# ESP32 register map
Vendor: ESPRESSIF SYSTEMS (SHANGHAI) CO., LTD.; Series: ESP32 Series; File version: 17
CPU: Xtensa LX6 r0p0, little endian, no MPU, FPU, 0 interrupt priority bits
Address unit: 32 bits
Registers are 32-bit, read-write, reset 0x0 unless marked. A register's access mark holds for its fields unless they carry their own. Offsets are from the block's base; [hi:lo] are bit positions; lines under a group give offsets from that group; {n}, {i} and the like mark numbered series.

## WIFI — MAC controller for Wi-Fi peripheral
Base 0x3FF73000
{0x0+0x40*i} FILTER_BANK{i} (i=0..1) group — Filter banks for frame reception. Bank zero is for the BSSID and bank one for the RA. Each filter bank has registers for two interfaces.
  {0x0+8j} ADDR_LOW{j} (j=0..3) — First 4 bytes of BSSID MAC address filter
  {0x4+8j} ADDR_HIGH{j} (j=0..3) — last 2 bytes of BSSID MAC address filter
    [15:0] ADDR
  {0x20+8j} MASK_LOW{j} (j=0..3) — First 4 bytes of BSSID MAC address filter mask
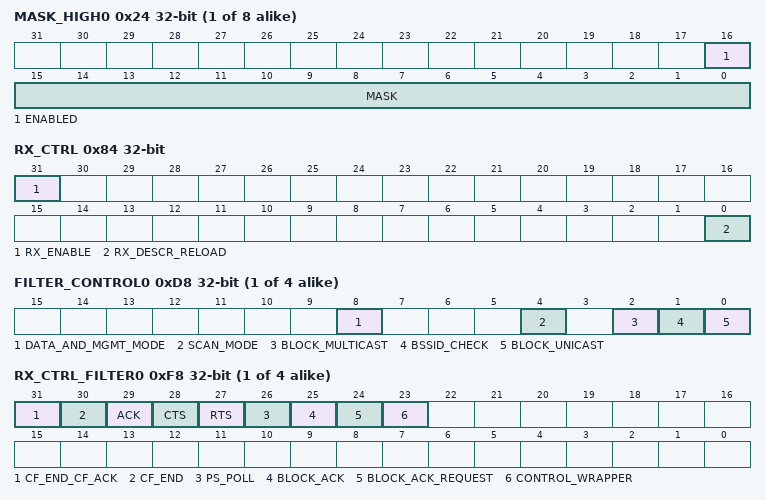
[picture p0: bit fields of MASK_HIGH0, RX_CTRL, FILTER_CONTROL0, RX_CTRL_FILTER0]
  {0x24+8j} MASK_HIGH{j} (j=0..3) — last 2 bytes of BSSID MAC address filter mask
    [16] ENABLED, [15:0] MASK
0x84 RX_CTRL — Controls the reception of frames
  [31] RX_ENABLE — Enable frame reception
  [0] RX_DESCR_RELOAD — Instruct the hardware to reload the RX descriptors
0x88 RX_DMA_LIST group
  0x00 RX_DESCR_BASE access not given — base address of the RX DMA list
  0x04 RX_DESCR_NEXT — next item in the RX DMA list
  0x08 RX_DESCR_LAST — last item in RX DMA list
{0xD8+4i} FILTER_CONTROL{i} (i=0..3) — Controls the RX filter for an interface
  [8] DATA_AND_MGMT_MODE — Receive everything except control frames
  [4] SCAN_MODE — Receive beacon frames
  [2] BLOCK_MULTICAST — Block multicast frames not matching the address filter
  [1] BSSID_CHECK — Check BSSID for filtering
  [0] BLOCK_UNICAST — Block unicast frames not matching the address filter
{0xF8+4i} RX_CTRL_FILTER{i} (i=0..3) — Configures which control frames pass the RX filter. Setting a bit lets that frame type pass the filter.
  [31] CF_END_CF_ACK — Filter CF-End+CF-Ack frames
  [30] CF_END — Filter CF-End frames
  [29] ACK — Filter ACK frames
  [28] CTS — Filter CTS frames
  [27] RTS — Filter RTS frames
  [26] PS_POLL — Filter PS-Poll frames
  [25] BLOCK_ACK — Filter Block ACK frames
  [24] BLOCK_ACK_REQUEST — Filter Block ACK Request frames
  [23] CONTROL_WRAPPER — Filter Control Wrapper frames
0x2BC HW_STAT_ACK_INT access not given
0x2C0 HW_STAT_RTS_INT access not given
0x2C4 HW_STAT_CTS_INT access not given
0x2C8 HW_STAT_RIFS_INT access not given
0x2CC HW_STAT_RX_SUCCESS access not given
0x2D0 HW_STAT_RX_END access not given
0x2D8 HW_STAT_HOP_ERR access not given
0x2DC HW_STAT_FULL2 access not given
0x2E0 HW_STAT_BLOCK_ERR access not given
0x800 CRYPTO_CONTROL group — Control registers for hardware crypto
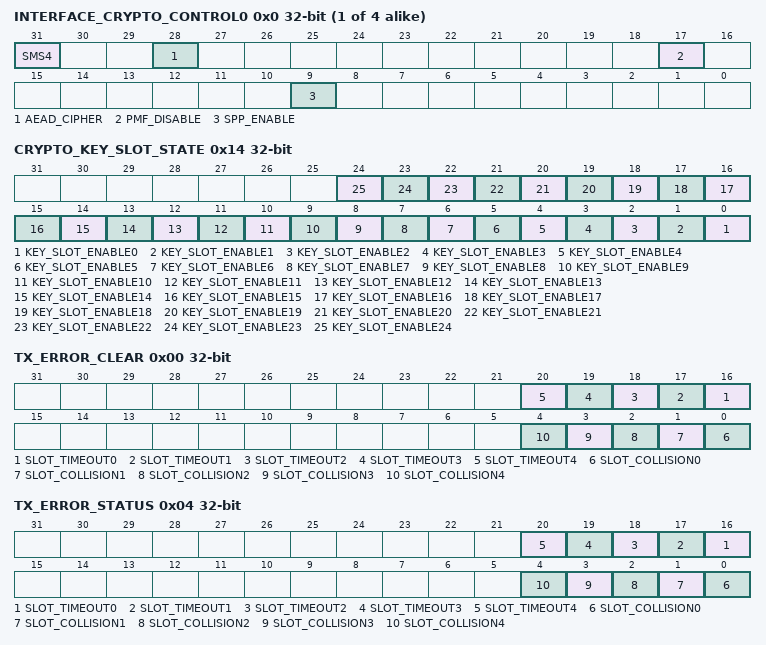
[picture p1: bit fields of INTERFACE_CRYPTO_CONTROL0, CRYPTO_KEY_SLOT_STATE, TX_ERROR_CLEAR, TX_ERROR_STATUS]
  {0x0+4j} INTERFACE_CRYPTO_CONTROL{j} (j=0..3) — Control over cryptographic parameters for a specific interface
    [31] SMS4 — Cipher is SMS4
    [28] AEAD_CIPHER — Does the cipher employ Authenticated Encryption with Associated Data (AEAD)
    [17] PMF_DISABLE — Disable Protected Management Frames (PMF)
    [9] SPP_ENABLE — Enable Signaling and Payload Protection (SPP) for A-MSDUs
  0x10 GENERAL_CRYPTO_CONTROL — Control over the whole crypto unit
  0x14 CRYPTO_KEY_SLOT_STATE — State of cryptographic key slots
    [n] KEY_SLOT_ENABLE{n} (n=0..24) — Enable the key slot corresponding to this bit
0xC00 MAC_TIME access not given — Current value of the MAC timer
0xC48 MAC_INTERRUPT group — Status and clear for the Wi-Fi MAC interrupt
  0x00 WIFI_INT_STATUS access not given — Interrupt status of WIFI peripheral
  0x04 WIFI_INT_CLEAR access not given — Interrupt status clear of WIFI peripheral
0xCB8 CTRL — Exact name and meaning unknown, used for initializing the MAC
0xCBC TXQ_STATE group — State of transmission queues
  0x00 TX_ERROR_CLEAR access not given — Clear the error status of a slot
    [n+16] SLOT_TIMEOUT{n} (n=0..4) — Timeout clear bit for a slot
    [n] SLOT_COLLISION{n} (n=0..4) — Collision clear bit for a slot
  0x04 TX_ERROR_STATUS access not given — Error status of a slot
    [n+16] SLOT_TIMEOUT{n} (n=0..4) — Timeout status bit for a slot
    [n] SLOT_COLLISION{n} (n=0..4) — Collision status bit for a slot
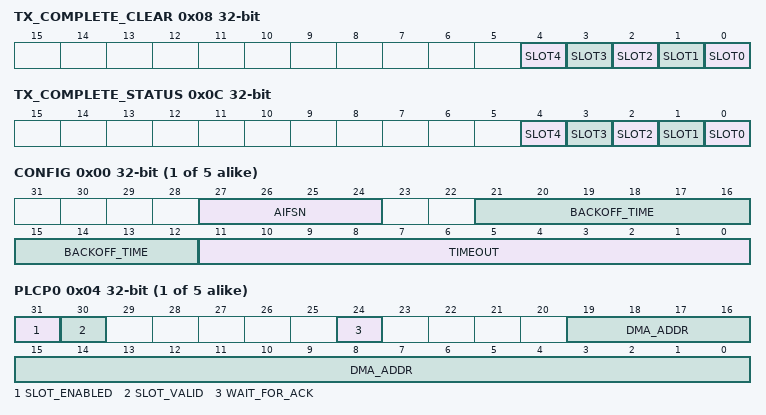
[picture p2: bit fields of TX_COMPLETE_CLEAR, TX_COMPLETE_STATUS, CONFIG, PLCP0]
  0x08 TX_COMPLETE_CLEAR access not given — Clear the completion status of a slot
    [n] SLOT{n} (n=0..4) — Clear bit for a slot
  0x0C TX_COMPLETE_STATUS access not given — Completion status of a slot
    [n] SLOT{n} (n=0..4) — Status bit for a slot
{0xCFC+8i} TX_SLOT_CONFIG{i} (i=0..4) group — Used to configure the TX slot.
  0x00 CONFIG
    [27:24] AIFSN, [21:12] BACKOFF_TIME, [11:0] TIMEOUT
  0x04 PLCP0
    [31] SLOT_ENABLED — Marks this slot as ready for transmission
    [30] SLOT_VALID — Marks this slot as valid
    [24] WAIT_FOR_ACK — Enables ACK timeouts
    [19:0] DMA_ADDR — Bottom bits of address of dma_item
0xD58 HW_STAT_TX_RTS access not given
0xD5C HW_STAT_TX_CTS access not given
0xD60 HW_STAT_TX_ACK access not given
0xD64 HW_STAT_TRCTS access not given
0xD68 HW_STAT_TRIGGER access not given
0xD6C HW_STAT_TX_HUNG access not given
0xD70 HW_STAT_PANIC access not given
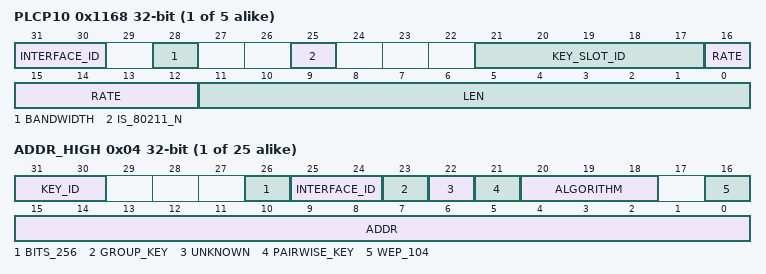
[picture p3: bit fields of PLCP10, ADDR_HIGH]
{0x1168+0x3C*i} PLCP1{i} (i=0..4)
  [31:30] INTERFACE_ID — ID of the interface this transmission is from
  [28] BANDWIDTH — Zero indicates 20MHz and one indicates 40MHz
  [25] IS_80211_N — Bit indicating if this is 802.11n
  [21:17] KEY_SLOT_ID — Key slot to use for encryption
  [16:12] RATE — Packet rate (see wifi_phy_rate_t)
  [11:0] LEN — Length of packet (in bytes)
{0x116C+0x3C*i} PLCP2{i} (i=0..4)
  [5] UNKNOWN — meaning unknown, set to one for TX
{0x1170+0x3C*i} HT_SIG{i} (i=0..4) — HT-SIG field in HT preamble
{0x1174+0x3C*i} HT_UNKNOWN{i} (i=0..4) — exact meaning and name unknown, related to HT
  [19:0] LENGTH — The length of the PPDU
{0x1178+0x3C*i} DURATION{i} (i=0..4) — duration of the frame exchange
{0x1180+0x3C*i} PMD{i} (i=0..4)
{0x1400+0x28*i} CRYPTO_KEY_SLOT{i} (i=0..24) group — Cryptographic keys for MPDU encapsulation and decapsulation
  0x00 ADDR_LOW — Lower four octets of the MAC address
  0x04 ADDR_HIGH — Higher two octets of the MAC address and config bits
    [31:30] KEY_ID — Protocol identifier of the key
    [26] BITS_256 — Key length is 256 bits
    [25:24] INTERFACE_ID — Index of the interface using the key
    [23] GROUP_KEY — Is this a group key
    [22] UNKNOWN — Meaning unknown set to 1 for all algorithms
    [21] PAIRWISE_KEY — Is this a pairwise key
    [20:18] ALGORITHM — In use algorithm
    [16] WEP_104 — Is the cipher WEP104
    [15:0] ADDR — Higher two octets of the MAC address
  {0x8+4j} KEY_VALUE{j} (j=0..7) — Actual key data
